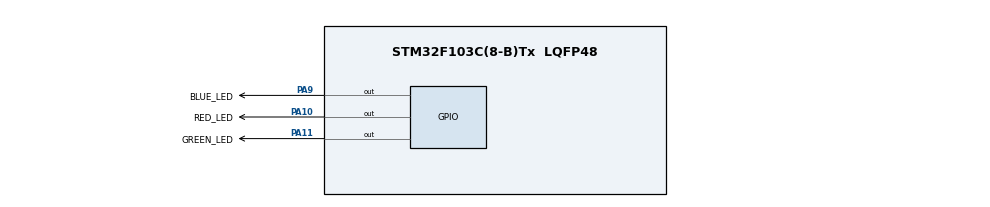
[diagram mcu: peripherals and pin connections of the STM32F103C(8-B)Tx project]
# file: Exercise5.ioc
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FREERTOS.Tasks01=defaultTask,24,128,StartDefaultTask,Default,NULL,Dynamic,NULL,NULL;GreenFlashTask,24,128,StartGreenFlashTask,Default,NULL,Dynamic,NULL,NULL;RedFlashTask,40,128,StartRedFlashTask,Default,NULL,Dynamic,NULL,NULL
FREERTOS.configUSE_NEWLIB_REENTRANT=1
Mcu.Family=STM32F1
Mcu.Name=STM32F103C(8-B)Tx
Mcu.Package=LQFP48
NVIC.PriorityGroup=NVIC_PRIORITYGROUP_4
NVIC.TIM1_UP_IRQn=true\:15\:0\:false\:false\:true\:false\:false\:true\:true
NVIC.TimeBase=TIM1_UP_IRQn
NVIC.TimeBaseIP=TIM1
PA10.GPIO_Label=RED_LED
PA10.Signal=GPIO_Output
PA11.GPIO_Label=GREEN_LED
PA11.Signal=GPIO_Output
PA13.Mode=Serial_Wire
PA13.Signal=SYS_JTMS-SWDIO
PA14.Mode=Serial_Wire
PA14.Signal=SYS_JTCK-SWCLK
PA9.GPIO_Label=BLUE_LED
PA9.Signal=GPIO_Output
PD0-OSC_IN.Mode=HSE-External-Oscillator
PD0-OSC_IN.Signal=RCC_OSC_IN
PD1-OSC_OUT.Mode=HSE-External-Oscillator
PD1-OSC_OUT.Signal=RCC_OSC_OUT
ProjectManager.HeapSize=0x200
ProjectManager.StackSize=0x400
ProjectManager.TargetToolchain=STM32CubeIDE
RCC.APB1Freq_Value=8000000
RCC.APB2Freq_Value=8000000
VP_FREERTOS_VS_CMSIS_V2.Mode=CMSIS_V2
VP_SYS_VS_tim1.Mode=TIM1
board=custom

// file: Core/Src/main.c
/* USER CODE BEGIN Header */
/**
  ******************************************************************************
  * @file           : main.c
  * @brief          : Main program body
  ******************************************************************************
  * @attention
  *
  * Copyright (c) 2024 STMicroelectronics.
  * All rights reserved.
  *
  * This software is licensed under terms that can be found in the LICENSE file
  * in the root directory of this software component.
  * If no LICENSE file comes with this software, it is provided AS-IS.
  *
  ******************************************************************************
  */
/* USER CODE END Header */
#include "main.h"
#include "cmsis_os.h"

/* Definitions for defaultTask */
osThreadId_t defaultTaskHandle;
const osThreadAttr_t defaultTask_attributes = {
  .name = "defaultTask",
  .stack_size = 128 * 4,
  .priority = (osPriority_t) osPriorityNormal,
};
/* Definitions for GreenFlashTask */
osThreadId_t GreenFlashTaskHandle;
const osThreadAttr_t GreenFlashTask_attributes = {
  .name = "GreenFlashTask",
  .stack_size = 128 * 4,
  .priority = (osPriority_t) osPriorityNormal,
};
/* Definitions for RedFlashTask */
osThreadId_t RedFlashTaskHandle;
const osThreadAttr_t RedFlashTask_attributes = {
  .name = "RedFlashTask",
  .stack_size = 128 * 4,
  .priority = (osPriority_t) osPriorityHigh,
};
/* USER CODE BEGIN PV */
volatile int resource_flag = 1; // 1 = resource free, 0 = resource busy

/* USER CODE END PV */

void SystemClock_Config(void);
static void MX_GPIO_Init(void);
void StartDefaultTask(void *argument);
void StartGreenFlashTask(void *argument);
void StartRedFlashTask(void *argument);

/* USER CODE BEGIN PFP */
void AccessSharedResource(const char* task_name) {
    if (resource_flag == 1) {
        resource_flag = 0; // Mark resource as busy
        // Simulate resource access
        HAL_Delay(100); // Simulate a critical section
        resource_flag = 1; // Release resource
    } else {
        // Contention occurred
        HAL_GPIO_WritePin(GPIOA, GPIO_PIN_5, GPIO_PIN_SET); // Turn on blue LED
        HAL_Delay(100);
        HAL_GPIO_WritePin(GPIOA, GPIO_PIN_5, GPIO_PIN_RESET); // Turn off blue LED
    }
}
/* USER CODE END PFP */

int main(void)
{

  /* MCU Configuration--------------------------------------------------------*/

  /* Reset of all peripherals, Initializes the Flash interface and the Systick. */
  HAL_Init();

  /* Configure the system clock */
  SystemClock_Config();

  /* Initialize all configured peripherals */
  MX_GPIO_Init();

  /* Init scheduler */
  osKernelInitialize();

  /* Create the thread(s) */
  /* creation of defaultTask */
  defaultTaskHandle = osThreadNew(StartDefaultTask, NULL, &defaultTask_attributes);

  /* creation of GreenFlashTask */
  GreenFlashTaskHandle = osThreadNew(StartGreenFlashTask, NULL, &GreenFlashTask_attributes);

  /* creation of RedFlashTask */
  RedFlashTaskHandle = osThreadNew(StartRedFlashTask, NULL, &RedFlashTask_attributes);

  /* Start scheduler */
  osKernelStart();

  /* We should never get here as control is now taken by the scheduler */

  /* Infinite loop */
  while (1)
  {

  }
}

void SystemClock_Config(void)
{
  RCC_OscInitTypeDef RCC_OscInitStruct = {0};
  RCC_ClkInitTypeDef RCC_ClkInitStruct = {0};

  /** Initializes the RCC Oscillators according to the specified parameters
  * in the RCC_OscInitTypeDef structure.
  */
  RCC_OscInitStruct.OscillatorType = RCC_OSCILLATORTYPE_HSI;
  RCC_OscInitStruct.HSIState = RCC_HSI_ON;
  RCC_OscInitStruct.HSICalibrationValue = RCC_HSICALIBRATION_DEFAULT;
  RCC_OscInitStruct.PLL.PLLState = RCC_PLL_NONE;
  if (HAL_RCC_OscConfig(&RCC_OscInitStruct) != HAL_OK)
  {
    Error_Handler();
  }

  /** Initializes the CPU, AHB and APB buses clocks
  */
  RCC_ClkInitStruct.ClockType = RCC_CLOCKTYPE_HCLK|RCC_CLOCKTYPE_SYSCLK
                              |RCC_CLOCKTYPE_PCLK1|RCC_CLOCKTYPE_PCLK2;
  RCC_ClkInitStruct.SYSCLKSource = RCC_SYSCLKSOURCE_HSI;
  RCC_ClkInitStruct.AHBCLKDivider = RCC_SYSCLK_DIV1;
  RCC_ClkInitStruct.APB1CLKDivider = RCC_HCLK_DIV1;
  RCC_ClkInitStruct.APB2CLKDivider = RCC_HCLK_DIV1;

  if (HAL_RCC_ClockConfig(&RCC_ClkInitStruct, FLASH_LATENCY_0) != HAL_OK)
  {
    Error_Handler();
  }
}

static void MX_GPIO_Init(void)
{
  GPIO_InitTypeDef GPIO_InitStruct = {0};

  /* GPIO Ports Clock Enable */
  __HAL_RCC_GPIOD_CLK_ENABLE();
  __HAL_RCC_GPIOA_CLK_ENABLE();

  /*Configure GPIO pin Output Level */
  HAL_GPIO_WritePin(GPIOA, BLUE_LED_Pin|RED_LED_Pin|GREEN_LED_Pin, GPIO_PIN_RESET);

  /*Configure GPIO pins : BLUE_LED_Pin RED_LED_Pin GREEN_LED_Pin */
  GPIO_InitStruct.Pin = BLUE_LED_Pin|RED_LED_Pin|GREEN_LED_Pin;
  GPIO_InitStruct.Mode = GPIO_MODE_OUTPUT_PP;
  GPIO_InitStruct.Pull = GPIO_NOPULL;
  GPIO_InitStruct.Speed = GPIO_SPEED_FREQ_LOW;
  HAL_GPIO_Init(GPIOA, &GPIO_InitStruct);

}

/* USER CODE BEGIN 4 */
void AccessSharedData(void) {
    if (resource_flag == 1) {
        // Set Start flag to Down to indicate resource is in use
        resource_flag = 0;
    } else {
        // Resource contention: Turn on Blue LED
        HAL_GPIO_WritePin(BLUE_LED_GPIO_Port, BLUE_LED_Pin, GPIO_PIN_RESET);
    }

    // Simulate read/write operations with a delay of 500 milliseconds
    HAL_Delay(500);

    // Set Start flag back to Up to indicate resource is free
    resource_flag = 1;

    // Turn off Blue LED (if it was turned on during contention)
    HAL_GPIO_WritePin(BLUE_LED_GPIO_Port, BLUE_LED_Pin, GPIO_PIN_SET);
}
/* USER CODE END 4 */

void StartDefaultTask(void *argument)
{
  for(;;)
  {
    osDelay(1);
  }
}

void StartGreenFlashTask(void *argument)
{
  /* USER CODE BEGIN StartGreenFlashTask */
  /* Infinite loop */
  for (;;) {
      HAL_GPIO_WritePin(GREEN_LED_GPIO_Port, GREEN_LED_Pin, GPIO_PIN_SET);
      AccessSharedData();
      // Turn off Green LED
      HAL_GPIO_WritePin(GREEN_LED_GPIO_Port, GREEN_LED_Pin, GPIO_PIN_RESET);
      // Delay for 500 milliseconds
      osDelay(500);
  }
  /* USER CODE END StartGreenFlashTask */
}

void StartRedFlashTask(void *argument)
{
  /* USER CODE BEGIN StartRedFlashTask */
  /* Infinite loop */
  for (;;) {
	  // Turn on Red LED
	  HAL_GPIO_WritePin(RED_LED_GPIO_Port, RED_LED_Pin, GPIO_PIN_SET);
	  AccessSharedData();
	  HAL_GPIO_WritePin(RED_LED_GPIO_Port, RED_LED_Pin, GPIO_PIN_RESET);
	       // Delay for 100 milliseconds
	  osDelay(100);
  }

}

  /* USER CODE END StartRedFlashTask */

void HAL_TIM_PeriodElapsedCallback(TIM_HandleTypeDef *htim)
{
  if (htim->Instance == TIM1) {
    HAL_IncTick();
  }
}

void Error_Handler(void)
{
  __disable_irq();
  while (1)
  {
  }
}
